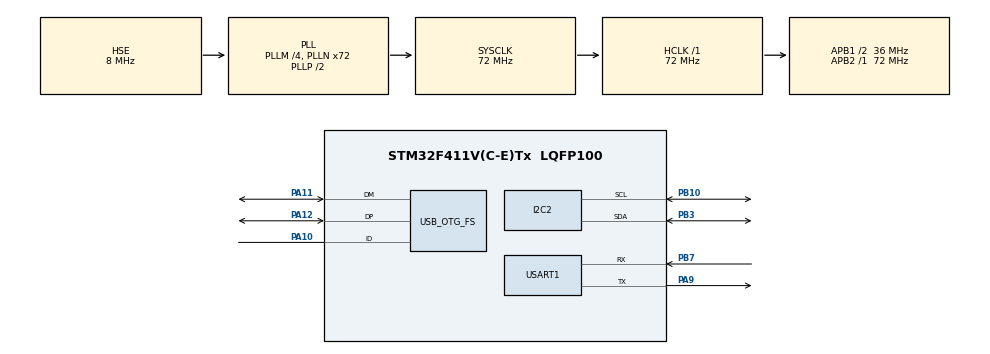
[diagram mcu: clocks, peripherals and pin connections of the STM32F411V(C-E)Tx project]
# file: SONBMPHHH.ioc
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Mcu.Family=STM32F4
PC15-OSC32_OUT.Mode=LSE-External-Oscillator
RCC.CortexFreq_Value=72000000
PA10.Mode=OTG/Dual_Role_Device
PB10.Mode=I2C
PH1\ -\ OSC_OUT.Mode=HSE-External-Oscillator
PA11.Mode=OTG/Dual_Role_Device
RCC.APB1CLKDivider=RCC_HCLK_DIV2
PC14-OSC32_IN.Signal=RCC_OSC32_IN
RCC.SYSCLKSource=RCC_SYSCLKSOURCE_PLLCLK
ProjectManager.StackSize=0x400
PA13.Signal=SYS_JTMS-SWDIO
PA9.Mode=Asynchronous
PA12.Signal=USB_OTG_FS_DP
PH0\ -\ OSC_IN.Mode=HSE-External-Oscillator
PH0\ -\ OSC_IN.Signal=RCC_OSC_IN
ProjectManager.TargetToolchain=STM32CubeIDE
RCC.HCLKFreq_Value=72000000
RCC.APB2TimFreq_Value=72000000
PA9.Signal=USART1_TX
PC15-OSC32_OUT.Signal=RCC_OSC32_OUT
RCC.AHBFreq_Value=72000000
PB10.Signal=I2C2_SCL
RCC.HSE_VALUE=8000000
PH1\ -\ OSC_OUT.Signal=RCC_OSC_OUT
PB3.Mode=I2C
board=custom
RCC.VCOOutputFreq_Value=144000000
RCC.APB2Freq_Value=72000000
PC14-OSC32_IN.Mode=LSE-External-Oscillator
PA14.Mode=Serial_Wire
PB7.Signal=USART1_RX
PA13.Mode=Serial_Wire
Mcu.Name=STM32F411V(C-E)Tx
RCC.48MHZClocksFreq_Value=48000000
PB3.Signal=I2C2_SDA
RCC.SYSCLKFreq_VALUE=72000000
Mcu.Package=LQFP100
PA12.Mode=OTG/Dual_Role_Device
USART1.VirtualMode=VM_ASYNC
PB7.Mode=Asynchronous
PA11.Signal=USB_OTG_FS_DM
PA10.Signal=USB_OTG_FS_ID
PA14.Signal=SYS_JTCK-SWCLK
ProjectManager.HeapSize=0x200
RCC.HSI_VALUE=16000000
RCC.PLLQ=3
NVIC.PriorityGroup=NVIC_PRIORITYGROUP_4
RCC.PLLM=4
RCC.PLLN=72
RCC.APB1TimFreq_Value=72000000
RCC.APB1Freq_Value=36000000

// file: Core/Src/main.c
/* USER CODE BEGIN Header */
/**
  ******************************************************************************
  * @file           : main.c
  * @brief          : Main program body
  ******************************************************************************
  * @attention
  *
  * <h2><center>&copy; Copyright (c) 2023 STMicroelectronics.
  * All rights reserved.</center></h2>
  *
  * This software component is licensed by ST under BSD 3-Clause license,
  * the "License"; You may not use this file except in compliance with the
  * License. You may obtain a copy of the License at:
  *                        opensource.org/licenses/BSD-3-Clause
  *
  ******************************************************************************
  */
/* USER CODE END Header */
#include "main.h"
#include "i2c.h"
#include "usart.h"
#include "usb_otg.h"
#include "gpio.h"

/* USER CODE BEGIN Includes */
#include "BMP280.h"
#include "stdio.h"

/* USER CODE END Includes */

/* USER CODE BEGIN PV */

double press;
double altitude;
double temperature;

/* USER CODE END PV */

void SystemClock_Config(void);

int main(void)
{

  /* MCU Configuration--------------------------------------------------------*/

  /* Reset of all peripherals, Initializes the Flash interface and the Systick. */
  HAL_Init();

  /* USER CODE BEGIN Init */
  HAL_Delay(1000);

  BMP280_Init(BMP280_MODE_NORMAL, BMP280_SAMPLING_X1, BMP280_SAMPLING_X1, BMP280_FILTER_OFF, BMP280_STANDBY_MS_1);

  /* USER CODE END Init */

  /* Configure the system clock */
  SystemClock_Config();

  /* Initialize all configured peripherals */
  MX_GPIO_Init();
  MX_I2C2_Init();
  MX_USART1_UART_Init();
  MX_USB_OTG_FS_USB_Init();

  /* Infinite loop */
  while (1)
  {

    /* USER CODE BEGIN 3 */
	  int i;
	   for(i=0;i<255;i++){
	   	if(HAL_I2C_IsDeviceReady(&hi2c2,i,1,100)==HAL_OK)
	   		break;
	   }

	  BMP280Temp_Pres_Calc(&temperature, &press);

	  	  	 altitude =  BMP280_readAltitude (press,1013.25);

	  	  	 HAL_Delay (500);
  }
  /* USER CODE END 3 */
}

void SystemClock_Config(void)
{
  RCC_OscInitTypeDef RCC_OscInitStruct = {0};
  RCC_ClkInitTypeDef RCC_ClkInitStruct = {0};

  /** Configure the main internal regulator output voltage
  */
  __HAL_RCC_PWR_CLK_ENABLE();
  __HAL_PWR_VOLTAGESCALING_CONFIG(PWR_REGULATOR_VOLTAGE_SCALE1);
  /** Initializes the RCC Oscillators according to the specified parameters
  * in the RCC_OscInitTypeDef structure.
  */
  RCC_OscInitStruct.OscillatorType = RCC_OSCILLATORTYPE_HSE;
  RCC_OscInitStruct.HSEState = RCC_HSE_ON;
  RCC_OscInitStruct.PLL.PLLState = RCC_PLL_ON;
  RCC_OscInitStruct.PLL.PLLSource = RCC_PLLSOURCE_HSE;
  RCC_OscInitStruct.PLL.PLLM = 4;
  RCC_OscInitStruct.PLL.PLLN = 72;
  RCC_OscInitStruct.PLL.PLLP = RCC_PLLP_DIV2;
  RCC_OscInitStruct.PLL.PLLQ = 3;
  if (HAL_RCC_OscConfig(&RCC_OscInitStruct) != HAL_OK)
  {
    Error_Handler();
  }
  /** Initializes the CPU, AHB and APB buses clocks
  */
  RCC_ClkInitStruct.ClockType = RCC_CLOCKTYPE_HCLK|RCC_CLOCKTYPE_SYSCLK
                              |RCC_CLOCKTYPE_PCLK1|RCC_CLOCKTYPE_PCLK2;
  RCC_ClkInitStruct.SYSCLKSource = RCC_SYSCLKSOURCE_PLLCLK;
  RCC_ClkInitStruct.AHBCLKDivider = RCC_SYSCLK_DIV1;
  RCC_ClkInitStruct.APB1CLKDivider = RCC_HCLK_DIV2;
  RCC_ClkInitStruct.APB2CLKDivider = RCC_HCLK_DIV1;

  if (HAL_RCC_ClockConfig(&RCC_ClkInitStruct, FLASH_LATENCY_2) != HAL_OK)
  {
    Error_Handler();
  }
}

void Error_Handler(void)
{
  __disable_irq();
  while (1)
  {
  }
}

/************************ (C) COPYRIGHT STMicroelectronics *****END OF FILE****/
